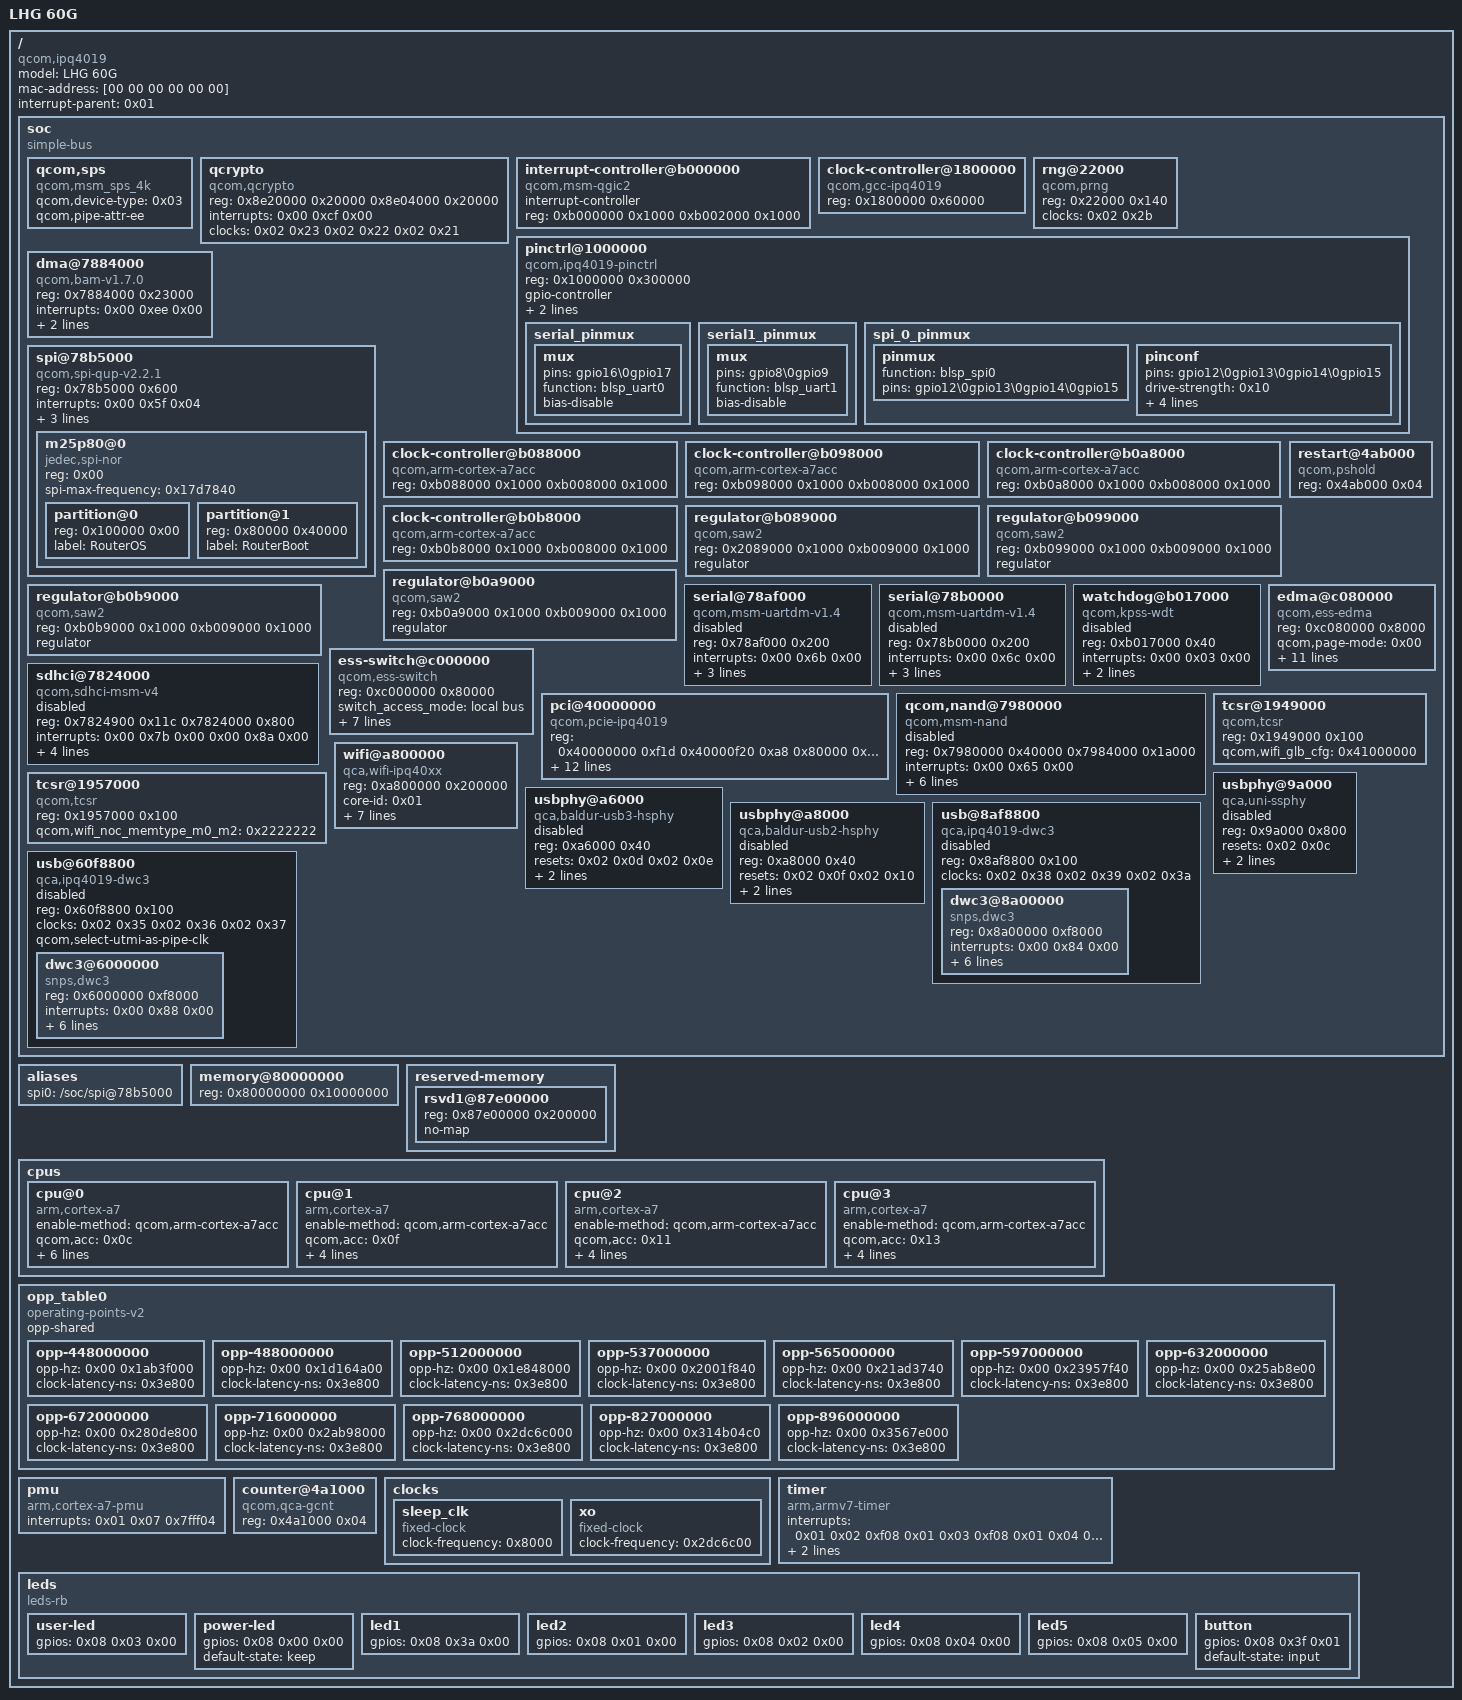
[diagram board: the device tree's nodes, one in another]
/dts-v1/;

/ {
	#address-cells = <0x01>;
	#size-cells = <0x01>;
	model = "LHG 60G";
	compatible = "qcom,ipq4019";
	mac-address = [00 00 00 00 00 00];
	interrupt-parent = <0x01>;

	soc {
		#address-cells = <0x01>;
		#size-cells = <0x01>;
		ranges;
		compatible = "simple-bus";

		qcom,sps {
			compatible = "qcom,msm_sps_4k";
			qcom,device-type = <0x03>;
			qcom,pipe-attr-ee;
		};

		qcrypto {
			compatible = "qcom,qcrypto";
			reg = <0x8e20000 0x20000 0x8e04000 0x20000>;
			reg-names = "crypto-base\0crypto-bam-base";
			interrupts = <0x00 0xcf 0x00>;
			clocks = <0x02 0x23 0x02 0x22 0x02 0x21>;
			clock-names = "core_clk\0bus_clk\0iface_clk";
		};

		interrupt-controller@b000000 {
			compatible = "qcom,msm-qgic2";
			interrupt-controller;
			#interrupt-cells = <0x03>;
			reg = <0xb000000 0x1000 0xb002000 0x1000>;
			phandle = <0x01>;
		};

		clock-controller@1800000 {
			compatible = "qcom,gcc-ipq4019";
			#clock-cells = <0x01>;
			#reset-cells = <0x01>;
			reg = <0x1800000 0x60000>;
			phandle = <0x02>;
		};

		rng@22000 {
			compatible = "qcom,prng";
			reg = <0x22000 0x140>;
			clocks = <0x02 0x2b>;
			clock-names = "core";
		};

		pinctrl@1000000 {
			compatible = "qcom,ipq4019-pinctrl";
			reg = <0x1000000 0x300000>;
			gpio-controller;
			#gpio-cells = <0x02>;
			interrupt-controller;
			#interrupt-cells = <0x02>;
			interrupts = <0x00 0xd0 0x00>;
			phandle = <0x08>;

			serial_pinmux {
				phandle = <0x05>;

				mux {
					pins = "gpio16\0gpio17";
					function = "blsp_uart0";
					bias-disable;
				};
			};

			serial1_pinmux {
				phandle = <0x06>;

				mux {
					pins = "gpio8\0gpio9";
					function = "blsp_uart1";
					bias-disable;
				};
			};

			spi_0_pinmux {
				phandle = <0x04>;

				pinmux {
					function = "blsp_spi0";
					pins = "gpio12\0gpio13\0gpio14\0gpio15";
				};

				pinconf {
					pins = "gpio12\0gpio13\0gpio14\0gpio15";
					drive-strength = <0x10>;
					bias-pull-up;
					bias-pull-down;
					vm-enable;
					pull-res = <0x02>;
				};
			};
		};

		dma@7884000 {
			compatible = "qcom,bam-v1.7.0";
			reg = <0x7884000 0x23000>;
			interrupts = <0x00 0xee 0x00>;
			clocks = <0x02 0x15>;
			clock-names = "bam_clk";
			#dma-cells = <0x01>;
			qcom,ee = <0x00>;
			phandle = <0x03>;
		};

		spi@78b5000 {
			compatible = "qcom,spi-qup-v2.2.1";
			reg = <0x78b5000 0x600>;
			interrupts = <0x00 0x5f 0x04>;
			clocks = <0x02 0x17 0x02 0x15>;
			clock-names = "core\0iface";
			#address-cells = <0x01>;
			#size-cells = <0x00>;
			dmas = <0x03 0x05 0x03 0x04>;
			dma-names = "rx\0tx";
			pinctrl-0 = <0x04>;
			pinctrl-names = "default";

			m25p80@0 {
				#address-cells = <0x01>;
				#size-cells = <0x01>;
				compatible = "jedec,spi-nor";
				reg = <0x00>;
				spi-max-frequency = <0x17d7840>;

				partition@0 {
					reg = <0x100000 0x00>;
					label = "RouterOS";
				};

				partition@1 {
					reg = <0x80000 0x40000>;
					label = "RouterBoot";
				};
			};
		};

		clock-controller@b088000 {
			compatible = "qcom,arm-cortex-a7acc";
			reg = <0xb088000 0x1000 0xb008000 0x1000>;
			phandle = <0x0c>;
		};

		clock-controller@b098000 {
			compatible = "qcom,arm-cortex-a7acc";
			reg = <0xb098000 0x1000 0xb008000 0x1000>;
			phandle = <0x0f>;
		};

		clock-controller@b0a8000 {
			compatible = "qcom,arm-cortex-a7acc";
			reg = <0xb0a8000 0x1000 0xb008000 0x1000>;
			phandle = <0x11>;
		};

		clock-controller@b0b8000 {
			compatible = "qcom,arm-cortex-a7acc";
			reg = <0xb0b8000 0x1000 0xb008000 0x1000>;
			phandle = <0x13>;
		};

		regulator@b089000 {
			compatible = "qcom,saw2";
			reg = <0x2089000 0x1000 0xb009000 0x1000>;
			regulator;
			phandle = <0x0d>;
		};

		regulator@b099000 {
			compatible = "qcom,saw2";
			reg = <0xb099000 0x1000 0xb009000 0x1000>;
			regulator;
			phandle = <0x10>;
		};

		regulator@b0a9000 {
			compatible = "qcom,saw2";
			reg = <0xb0a9000 0x1000 0xb009000 0x1000>;
			regulator;
			phandle = <0x12>;
		};

		regulator@b0b9000 {
			compatible = "qcom,saw2";
			reg = <0xb0b9000 0x1000 0xb009000 0x1000>;
			regulator;
			phandle = <0x14>;
		};

		serial@78af000 {
			compatible = "qcom,msm-uartdm-v1.4\0qcom,msm-uartdm";
			reg = <0x78af000 0x200>;
			interrupts = <0x00 0x6b 0x00>;
			clocks = <0x02 0x1a 0x02 0x15>;
			clock-names = "core\0iface";
			dmas = <0x03 0x01 0x03 0x00>;
			dma-names = "rx\0tx";
			pinctrl-0 = <0x05>;
			pinctrl-names = "default";
			status = "disabled";
		};

		serial@78b0000 {
			compatible = "qcom,msm-uartdm-v1.4\0qcom,msm-uartdm";
			reg = <0x78b0000 0x200>;
			interrupts = <0x00 0x6c 0x00>;
			clocks = <0x02 0x1b 0x02 0x15>;
			clock-names = "core\0iface";
			dmas = <0x03 0x03 0x03 0x02>;
			dma-names = "rx\0tx";
			pinctrl-0 = <0x06>;
			pinctrl-names = "default";
			status = "disabled";
		};

		watchdog@b017000 {
			compatible = "qcom,kpss-wdt\0qcom,kpss-wdt-ipq4019";
			reg = <0xb017000 0x40>;
			interrupt-names = "bark_irq";
			interrupts = <0x00 0x03 0x00>;
			clocks = <0x07>;
			timeout-sec = <0x0a>;
			status = "disabled";
		};

		restart@4ab000 {
			compatible = "qcom,pshold";
			reg = <0x4ab000 0x04>;
		};

		ess-switch@c000000 {
			compatible = "qcom,ess-switch";
			reg = <0xc000000 0x80000>;
			switch_access_mode = "local bus";
			resets = <0x02 0x1d 0x02 0x4e 0x02 0x4f 0x02 0x50 0x02 0x51 0x02 0x52>;
			reset-names = "ess_rst\0ess_mac1_clk_dis\0ess_mac2_clk_dis\0ess_mac3_clk_dis\0ess_mac4_clk_dis\0ess_mac5_clk_dis";
			switch_cpu_bmp = <0x01>;
			switch_lan_bmp = <0x1e>;
			switch_wan_bmp = <0x20>;
			switch_mac_mode = <0x00>;
			switch_initvlas = <0x7c 0x54>;
		};

		edma@c080000 {
			compatible = "qcom,ess-edma";
			reg = <0xc080000 0x8000>;
			qcom,page-mode = <0x00>;
			qcom,rx_head_buf_size = <0x604>;
			qcom,wan_port_id_mask = <0x10>;
			qcom,mdio_supported;
			qcom,phy_mdio_addr = <0x04>;
			qcom,poll_required = <0x01>;
			qcom,forced_speed = <0x3e8>;
			qcom,forced_duplex = <0x01>;
			interrupts = <0x00 0x41 0x01 0x00 0x42 0x01 0x00 0x43 0x01 0x00 0x44 0x01 0x00 0x45 0x01 0x00 0x46 0x01 0x00 0x47 0x01 0x00 0x48 0x01 0x00 0x49 0x01 0x00 0x4a 0x01 0x00 0x4b 0x01 0x00 0x4c 0x01 0x00 0x4d 0x01 0x00 0x4e 0x01 0x00 0x4f 0x01 0x00 0x50 0x01 0x00 0xf0 0x01 0x00 0xf1 0x01 0x00 0xf2 0x01 0x00 0xf3 0x01 0x00 0xf4 0x01 0x00 0xf5 0x01 0x00 0xf6 0x01 0x00 0xf7 0x01 0x00 0xf8 0x01 0x00 0xf9 0x01 0x00 0xfa 0x01 0x00 0xfb 0x01 0x00 0xfc 0x01 0x00 0xfd 0x01 0x00 0xfe 0x01 0x00 0xff 0x01>;
			clocks = <0x02 0x24>;
			clock-names = "ess_clk";
			port_map = <0x100004 0xffffffff>;
		};

		pci@40000000 {
			compatible = "qcom,pcie-ipq4019";
			reg = <0x40000000 0xf1d 0x40000f20 0xa8 0x80000 0x2000 0x40100000 0x1000 0x99000 0x800>;
			reg-names = "dbi\0elbi\0parf\0config\0pciephy";
			device_type = "pci";
			linux,pci-domain = <0x00>;
			bus-range = <0x00 0xff>;
			num-lanes = <0x01>;
			#address-cells = <0x03>;
			#size-cells = <0x02>;
			ranges = <0x81000000 0x00 0x40200000 0x40200000 0x00 0x100000 0x82000010 0x00 0x40300000 0x40300000 0x00 0xd00000>;
			interrupts = <0x00 0x8d 0x00>;
			interrupt-names = "msi";
			#interrupt-cells = <0x01>;
			interrupt-map-mask = <0x00 0x00 0x00 0x07>;
			interrupt-map = <0x00 0x00 0x00 0x01 0x01 0x00 0x8e 0x04 0x00 0x00 0x00 0x02 0x01 0x00 0x8f 0x04 0x00 0x00 0x00 0x03 0x01 0x00 0x90 0x04 0x00 0x00 0x00 0x04 0x01 0x00 0x91 0x04>;
			clocks = <0x02 0x27 0x02 0x28 0x02 0x29>;
			clock-names = "aux\0master_bus\0slave_bus";
			resets = <0x02 0x1c 0x02 0x1b 0x02 0x1a 0x02 0x19 0x02 0x18 0x02 0x17 0x02 0x16 0x02 0x15 0x02 0x14 0x02 0x13 0x02 0x12 0x02 0x11>;
			reset-names = "axi_m\0axi_s\0pipe\0axi_m_vmid\0axi_s_xpu\0parf\0phy\0axi_m_sticky\0pipe_sticky\0pwr\0ahb\0phy_ahb";
			status = "ok";
			perst-gpio = <0x08 0x2a 0x00>;
			booster-gpio = <0x08 0x42 0x00>;
		};

		qcom,nand@7980000 {
			compatible = "qcom,msm-nand";
			reg = <0x7980000 0x40000 0x7984000 0x1a000>;
			reg-names = "nand_phys\0bam_phys";
			interrupts = <0x00 0x65 0x00>;
			interrupt-names = "bam_irq";
			qcom,msm-bus,name = "qpic_nand";
			qcom,msm-bus,num-cases = <0x02>;
			qcom,msm-bus,num-paths = <0x01>;
			qcom,msm-bus,vectors-KBps = <0x5b 0x200 0x00 0x00 0x5b 0x200 0x61a80 0xc3500>;
			clock-names = "iface_clk\0core_clk";
			clocks = <0x02 0x2c 0x02 0x2d>;
			status = "disabled";
		};

		sdhci@7824000 {
			compatible = "qcom,sdhci-msm-v4";
			reg = <0x7824900 0x11c 0x7824000 0x800>;
			reg-names = "hc_mem\0core_mem";
			interrupts = <0x00 0x7b 0x00 0x00 0x8a 0x00>;
			interrupt-names = "hc_irq\0pwr_irq";
			bus-width = <0x08>;
			clocks = <0x02 0x2f 0x02 0x2e>;
			clock-names = "core\0iface";
			cpu-ipq40xx;
			cd-gpios = <0x08 0x16 0x01>;
			status = "disabled";
		};

		tcsr@1949000 {
			compatible = "qcom,tcsr";
			reg = <0x1949000 0x100>;
			qcom,wifi_glb_cfg = <0x41000000>;
		};

		tcsr@1957000 {
			compatible = "qcom,tcsr";
			reg = <0x1957000 0x100>;
			qcom,wifi_noc_memtype_m0_m2 = <0x2222222>;
		};

		wifi@a800000 {
			compatible = "qca,wifi-ipq40xx";
			reg = <0xa800000 0x200000>;
			core-id = <0x01>;
			resets = <0x02 0x06 0x02 0x07 0x02 0x08 0x02 0x09 0x02 0x0a 0x02 0x0b>;
			reset-names = "wifi_cpu_init\0wifi_radio_srif\0wifi_radio_warm\0wifi_radio_cold\0wifi_core_warm\0wifi_core_cold";
			clocks = <0x02 0x3e 0x02 0x3f 0x02 0x40>;
			clock-names = "wifi_wcss_cmd\0wifi_wcss_ref\0wifi_wcss_rtc";
			interrupts = <0x00 0x30 0x01 0x00 0x31 0x01 0x00 0x32 0x01 0x00 0x33 0x01 0x00 0x34 0x01 0x00 0x35 0x01 0x00 0x36 0x01 0x00 0x37 0x01 0x00 0x38 0x01 0x00 0x39 0x01 0x00 0x3a 0x01 0x00 0x3b 0x01 0x00 0x3c 0x01 0x00 0x3d 0x01 0x00 0x3e 0x01 0x00 0x3f 0x01 0x00 0xa9 0x00>;
			interrupt-names = "msi0\0msi1\0msi2\0msi3\0msi4\0msi5\0msi6\0msi7\0msi8\0msi9\0msi10\0msi11\0msi12\0msi13\0msi14\0msi15\0legacy";
			status = "ok";
			qca,msi_addr = <0xb006040>;
			qca,msi_base = <0x50>;
		};

		usbphy@9a000 {
			compatible = "qca,uni-ssphy";
			reg = <0x9a000 0x800>;
			reg-names = "phy_base";
			resets = <0x02 0x0c>;
			reset-names = "por_rst";
			qca,emulation = <0x00>;
			qca,host = <0x01>;
			status = "disabled";
			phandle = <0x0a>;
		};

		usbphy@a6000 {
			compatible = "qca,baldur-usb3-hsphy";
			reg = <0xa6000 0x40>;
			reg-names = "phy_base";
			resets = <0x02 0x0d 0x02 0x0e>;
			reset-names = "por_rst\0srif_rst";
			qca,emulation = <0x00>;
			qca,host = <0x01>;
			status = "disabled";
			phandle = <0x09>;
		};

		usbphy@a8000 {
			compatible = "qca,baldur-usb2-hsphy";
			reg = <0xa8000 0x40>;
			reg-names = "phy_base";
			resets = <0x02 0x0f 0x02 0x10>;
			reset-names = "por_rst\0srif_rst";
			qca,emulation = <0x00>;
			qca,host = <0x01>;
			status = "disabled";
			phandle = <0x0b>;
		};

		usb@8af8800 {
			compatible = "qca,ipq4019-dwc3";
			reg = <0x8af8800 0x100>;
			#address-cells = <0x01>;
			#size-cells = <0x01>;
			clocks = <0x02 0x38 0x02 0x39 0x02 0x3a>;
			clock-names = "core\0sleep\0mock_utmi";
			ranges;
			status = "disabled";

			dwc3@8a00000 {
				compatible = "snps,dwc3";
				reg = <0x8a00000 0xf8000>;
				interrupts = <0x00 0x84 0x00>;
				usb-phy = <0x09 0x0a>;
				phy-names = "usb2-phy\0usb3-phy";
				dr_mode = "host";
				usb2-susphy-quirk;
				snps,dis_u3_susphy_quirk;
				snps,dis_u2_susphy_quirk;
				snps,parkmode-disable-ss-quirk;
			};
		};

		usb@60f8800 {
			compatible = "qca,ipq4019-dwc3";
			reg = <0x60f8800 0x100>;
			#address-cells = <0x01>;
			#size-cells = <0x01>;
			clocks = <0x02 0x35 0x02 0x36 0x02 0x37>;
			clock-names = "core\0sleep\0mock_utmi";
			ranges;
			qcom,select-utmi-as-pipe-clk;
			status = "disabled";

			dwc3@6000000 {
				compatible = "snps,dwc3";
				reg = <0x6000000 0xf8000>;
				interrupts = <0x00 0x88 0x00>;
				usb-phy = <0x0b>;
				phy-names = "usb2-phy";
				dr_mode = "host";
				usb2-susphy-quirk;
				snps,dis_u3_susphy_quirk;
				snps,dis_u2_susphy_quirk;
				snps,parkmode-disable-ss-quirk;
			};
		};
	};

	aliases {
		spi0 = "/soc/spi@78b5000";
	};

	memory@80000000 {
		device_type = "memory";
		reg = <0x80000000 0x10000000>;
	};

	reserved-memory {
		#address-cells = <0x01>;
		#size-cells = <0x01>;
		ranges;

		rsvd1@87e00000 {
			reg = <0x87e00000 0x200000>;
			no-map;
		};
	};

	cpus {
		#address-cells = <0x01>;
		#size-cells = <0x00>;

		cpu@0 {
			device_type = "cpu";
			compatible = "arm,cortex-a7";
			enable-method = "qcom,arm-cortex-a7acc";
			qcom,acc = <0x0c>;
			qcom,saw = <0x0d>;
			reg = <0x00>;
			clocks = <0x02 0x09>;
			clock-frequency = <0x00>;
			operating-points-v2 = <0x0e>;
			clock-latency = <0x3e800>;
		};

		cpu@1 {
			device_type = "cpu";
			compatible = "arm,cortex-a7";
			enable-method = "qcom,arm-cortex-a7acc";
			qcom,acc = <0x0f>;
			qcom,saw = <0x10>;
			reg = <0x01>;
			clocks = <0x02 0x09>;
			clock-frequency = <0x00>;
		};

		cpu@2 {
			device_type = "cpu";
			compatible = "arm,cortex-a7";
			enable-method = "qcom,arm-cortex-a7acc";
			qcom,acc = <0x11>;
			qcom,saw = <0x12>;
			reg = <0x02>;
			clocks = <0x02 0x09>;
			clock-frequency = <0x00>;
		};

		cpu@3 {
			device_type = "cpu";
			compatible = "arm,cortex-a7";
			enable-method = "qcom,arm-cortex-a7acc";
			qcom,acc = <0x13>;
			qcom,saw = <0x14>;
			reg = <0x03>;
			clocks = <0x02 0x09>;
			clock-frequency = <0x00>;
		};
	};

	opp_table0 {
		compatible = "operating-points-v2";
		opp-shared;
		phandle = <0x0e>;

		opp-448000000 {
			opp-hz = <0x00 0x1ab3f000>;
			clock-latency-ns = <0x3e800>;
		};

		opp-488000000 {
			opp-hz = <0x00 0x1d164a00>;
			clock-latency-ns = <0x3e800>;
		};

		opp-512000000 {
			opp-hz = <0x00 0x1e848000>;
			clock-latency-ns = <0x3e800>;
		};

		opp-537000000 {
			opp-hz = <0x00 0x2001f840>;
			clock-latency-ns = <0x3e800>;
		};

		opp-565000000 {
			opp-hz = <0x00 0x21ad3740>;
			clock-latency-ns = <0x3e800>;
		};

		opp-597000000 {
			opp-hz = <0x00 0x23957f40>;
			clock-latency-ns = <0x3e800>;
		};

		opp-632000000 {
			opp-hz = <0x00 0x25ab8e00>;
			clock-latency-ns = <0x3e800>;
		};

		opp-672000000 {
			opp-hz = <0x00 0x280de800>;
			clock-latency-ns = <0x3e800>;
		};

		opp-716000000 {
			opp-hz = <0x00 0x2ab98000>;
			clock-latency-ns = <0x3e800>;
		};

		opp-768000000 {
			opp-hz = <0x00 0x2dc6c000>;
			clock-latency-ns = <0x3e800>;
		};

		opp-827000000 {
			opp-hz = <0x00 0x314b04c0>;
			clock-latency-ns = <0x3e800>;
		};

		opp-896000000 {
			opp-hz = <0x00 0x3567e000>;
			clock-latency-ns = <0x3e800>;
		};
	};

	pmu {
		compatible = "arm,cortex-a7-pmu";
		interrupts = <0x01 0x07 0x7fff04>;
	};

	counter@4a1000 {
		compatible = "qcom,qca-gcnt";
		reg = <0x4a1000 0x04>;
	};

	clocks {

		sleep_clk {
			compatible = "fixed-clock";
			clock-frequency = <0x8000>;
			#clock-cells = <0x00>;
			phandle = <0x07>;
		};

		xo {
			compatible = "fixed-clock";
			clock-frequency = <0x2dc6c00>;
			#clock-cells = <0x00>;
		};
	};

	timer {
		compatible = "arm,armv7-timer";
		interrupts = <0x01 0x02 0xf08 0x01 0x03 0xf08 0x01 0x04 0xf08 0x01 0x01 0xf08>;
		clock-frequency = <0x2dc6c00>;
		always-on;
	};

	leds {
		compatible = "leds-rb";

		user-led {
			gpios = <0x08 0x03 0x00>;
		};

		power-led {
			gpios = <0x08 0x00 0x00>;
			default-state = "keep";
		};

		led1 {
			gpios = <0x08 0x3a 0x00>;
		};

		led2 {
			gpios = <0x08 0x01 0x00>;
		};

		led3 {
			gpios = <0x08 0x02 0x00>;
		};

		led4 {
			gpios = <0x08 0x04 0x00>;
		};

		led5 {
			gpios = <0x08 0x05 0x00>;
		};

		button {
			gpios = <0x08 0x3f 0x01>;
			default-state = "input";
		};
	};
};
